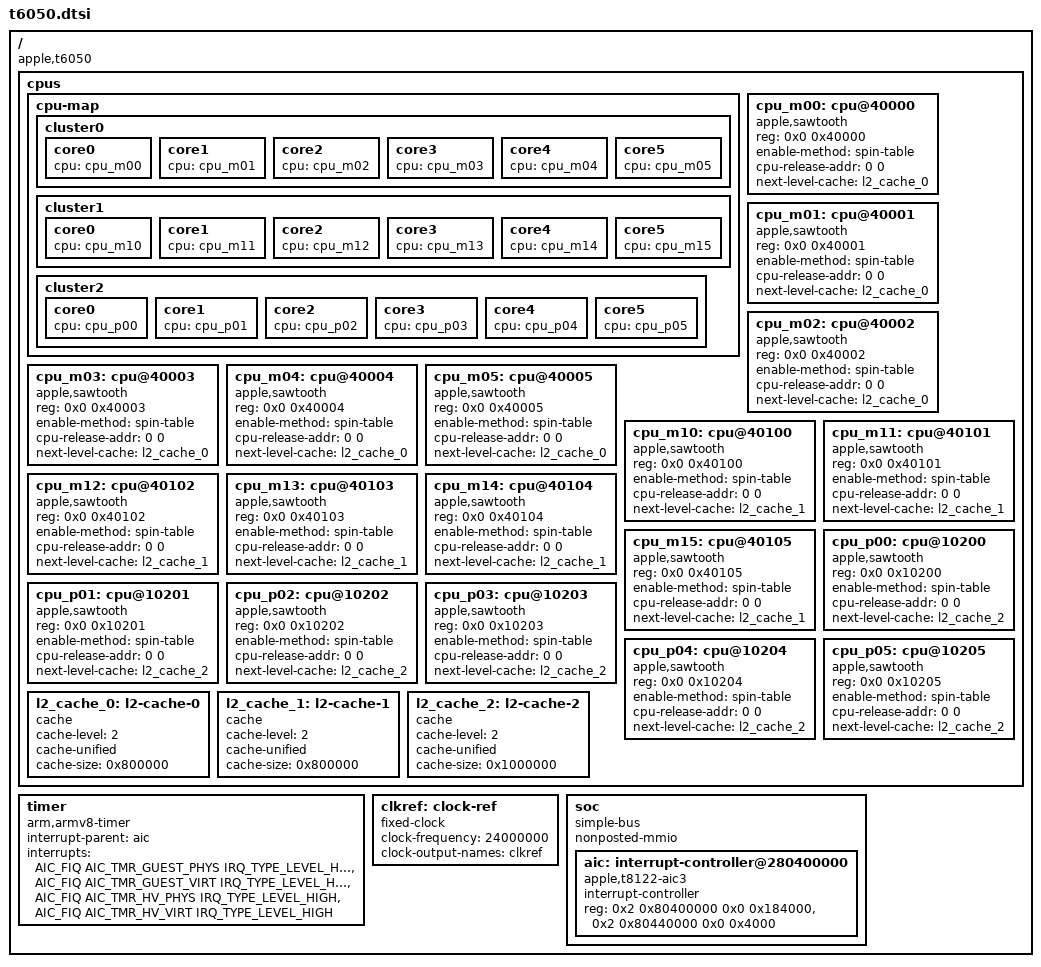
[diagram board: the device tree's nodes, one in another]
// SPDX-License-Identifier: GPL-2.0+ OR MIT
/*
 * Apple T6050 "M5 Pro / Max" SoC
 *
 * Copyright The Asahi Linux Contributors
 */

#include <dt-bindings/interrupt-controller/apple-aic.h>
#include <dt-bindings/interrupt-controller/irq.h>

/ {
	compatible = "apple,t6050", "apple,arm-platform";

	#address-cells = <2>;
	#size-cells = <2>;

	cpus {
		#address-cells = <2>;
		#size-cells = <0>;

		cpu-map {
			cluster0 {
				core0 {
					cpu = <&cpu_m00>;
				};
				core1 {
					cpu = <&cpu_m01>;
				};
				core2 {
					cpu = <&cpu_m02>;
				};
				core3 {
					cpu = <&cpu_m03>;
				};
				core4 {
					cpu = <&cpu_m04>;
				};
				core5 {
					cpu = <&cpu_m05>;
				};
			};
			cluster1 {
				core0 {
					cpu = <&cpu_m10>;
				};
				core1 {
					cpu = <&cpu_m11>;
				};
				core2 {
					cpu = <&cpu_m12>;
				};
				core3 {
					cpu = <&cpu_m13>;
				};
				core4 {
					cpu = <&cpu_m14>;
				};
				core5 {
					cpu = <&cpu_m15>;
				};
			};
			cluster2 {
				core0 {
					cpu = <&cpu_p00>;
				};
				core1 {
					cpu = <&cpu_p01>;
				};
				core2 {
					cpu = <&cpu_p02>;
				};
				core3 {
					cpu = <&cpu_p03>;
				};
				core4 {
					cpu = <&cpu_p04>;
				};
				core5 {
					cpu = <&cpu_p05>;
				};
			};
		};

		cpu_m00: cpu@40000 {
			compatible = "apple,sawtooth";
			device_type = "cpu";
			reg = <0x0 0x40000>;
			enable-method = "spin-table";
			cpu-release-addr = <0 0>;
			next-level-cache = <&l2_cache_0>;
		};

		cpu_m01: cpu@40001 {
			compatible = "apple,sawtooth";
			device_type = "cpu";
			reg = <0x0 0x40001>;
			enable-method = "spin-table";
			cpu-release-addr = <0 0>;
			next-level-cache = <&l2_cache_0>;
		};

		cpu_m02: cpu@40002 {
			compatible = "apple,sawtooth";
			device_type = "cpu";
			reg = <0x0 0x40002>;
			enable-method = "spin-table";
			cpu-release-addr = <0 0>;
			next-level-cache = <&l2_cache_0>;
		};

		cpu_m03: cpu@40003 {
			compatible = "apple,sawtooth";
			device_type = "cpu";
			reg = <0x0 0x40003>;
			enable-method = "spin-table";
			cpu-release-addr = <0 0>;
			next-level-cache = <&l2_cache_0>;
		};

		cpu_m04: cpu@40004 {
			compatible = "apple,sawtooth";
			device_type = "cpu";
			reg = <0x0 0x40004>;
			enable-method = "spin-table";
			cpu-release-addr = <0 0>;
			next-level-cache = <&l2_cache_0>;
		};

		cpu_m05: cpu@40005 {
			compatible = "apple,sawtooth";
			device_type = "cpu";
			reg = <0x0 0x40005>;
			enable-method = "spin-table";
			cpu-release-addr = <0 0>;
			next-level-cache = <&l2_cache_0>;
		};

		cpu_m10: cpu@40100 {
			compatible = "apple,sawtooth";
			device_type = "cpu";
			reg = <0x0 0x40100>;
			enable-method = "spin-table";
			cpu-release-addr = <0 0>;
			next-level-cache = <&l2_cache_1>;
		};

		cpu_m11: cpu@40101 {
			compatible = "apple,sawtooth";
			device_type = "cpu";
			reg = <0x0 0x40101>;
			enable-method = "spin-table";
			cpu-release-addr = <0 0>;
			next-level-cache = <&l2_cache_1>;
		};

		cpu_m12: cpu@40102 {
			compatible = "apple,sawtooth";
			device_type = "cpu";
			reg = <0x0 0x40102>;
			enable-method = "spin-table";
			cpu-release-addr = <0 0>;
			next-level-cache = <&l2_cache_1>;
		};

		cpu_m13: cpu@40103 {
			compatible = "apple,sawtooth";
			device_type = "cpu";
			reg = <0x0 0x40103>;
			enable-method = "spin-table";
			cpu-release-addr = <0 0>;
			next-level-cache = <&l2_cache_1>;
		};

		cpu_m14: cpu@40104 {
			compatible = "apple,sawtooth";
			device_type = "cpu";
			reg = <0x0 0x40104>;
			enable-method = "spin-table";
			cpu-release-addr = <0 0>;
			next-level-cache = <&l2_cache_1>;
		};

		cpu_m15: cpu@40105 {
			compatible = "apple,sawtooth";
			device_type = "cpu";
			reg = <0x0 0x40105>;
			enable-method = "spin-table";
			cpu-release-addr = <0 0>;
			next-level-cache = <&l2_cache_1>;
		};

		cpu_p00: cpu@10200 {
			compatible = "apple,sawtooth";
			device_type = "cpu";
			reg = <0x0 0x10200>;
			enable-method = "spin-table";
			cpu-release-addr = <0 0>;
			next-level-cache = <&l2_cache_2>;
		};

		cpu_p01: cpu@10201 {
			compatible = "apple,sawtooth";
			device_type = "cpu";
			reg = <0x0 0x10201>;
			enable-method = "spin-table";
			cpu-release-addr = <0 0>;
			next-level-cache = <&l2_cache_2>;
		};

		cpu_p02: cpu@10202 {
			compatible = "apple,sawtooth";
			device_type = "cpu";
			reg = <0x0 0x10202>;
			enable-method = "spin-table";
			cpu-release-addr = <0 0>;
			next-level-cache = <&l2_cache_2>;
		};

		cpu_p03: cpu@10203 {
			compatible = "apple,sawtooth";
			device_type = "cpu";
			reg = <0x0 0x10203>;
			enable-method = "spin-table";
			cpu-release-addr = <0 0>;
			next-level-cache = <&l2_cache_2>;
		};

		cpu_p04: cpu@10204 {
			compatible = "apple,sawtooth";
			device_type = "cpu";
			reg = <0x0 0x10204>;
			enable-method = "spin-table";
			cpu-release-addr = <0 0>;
			next-level-cache = <&l2_cache_2>;
		};

		cpu_p05: cpu@10205 {
			compatible = "apple,sawtooth";
			device_type = "cpu";
			reg = <0x0 0x10205>;
			enable-method = "spin-table";
			cpu-release-addr = <0 0>;
			next-level-cache = <&l2_cache_2>;
		};

		l2_cache_0: l2-cache-0 {
			compatible = "cache";
			cache-level = <2>;
			cache-unified;
			cache-size = <0x800000>;
		};

		l2_cache_1: l2-cache-1 {
			compatible = "cache";
			cache-level = <2>;
			cache-unified;
			cache-size = <0x800000>;
		};

		l2_cache_2: l2-cache-2 {
			compatible = "cache";
			cache-level = <2>;
			cache-unified;
			cache-size = <0x1000000>;
		};
	};

	timer {
		compatible = "arm,armv8-timer";
		interrupt-parent = <&aic>;
		interrupt-names = "phys", "virt", "hyp-phys", "hyp-virt";
		interrupts = <AIC_FIQ AIC_TMR_GUEST_PHYS IRQ_TYPE_LEVEL_HIGH>,
			     <AIC_FIQ AIC_TMR_GUEST_VIRT IRQ_TYPE_LEVEL_HIGH>,
			     <AIC_FIQ AIC_TMR_HV_PHYS IRQ_TYPE_LEVEL_HIGH>,
			     <AIC_FIQ AIC_TMR_HV_VIRT IRQ_TYPE_LEVEL_HIGH>;
	};

	clkref: clock-ref {
		compatible = "fixed-clock";
		#clock-cells = <0>;
		clock-frequency = <24000000>;
		clock-output-names = "clkref";
	};

	soc {
		compatible = "simple-bus";
		#address-cells = <2>;
		#size-cells = <2>;

		ranges;
		nonposted-mmio;

		aic: interrupt-controller@280400000 {
			compatible = "apple,t8122-aic3";
			#interrupt-cells = <3>;
			interrupt-controller;
			reg = <0x2 0x80400000 0x0 0x184000>,
			      <0x2 0x80440000 0x0 0x4000>;
			reg-names = "core", "event";
			//power-domains = <&ps_aic>;
		};
	};
};
